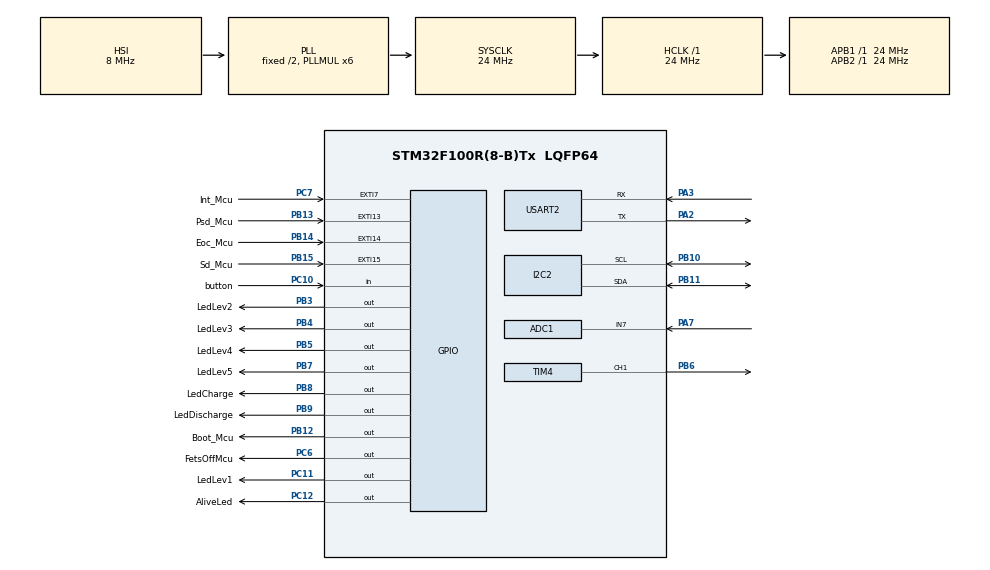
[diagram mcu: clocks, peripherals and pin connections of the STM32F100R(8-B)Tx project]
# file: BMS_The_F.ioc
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ADC1.Channel-0\#ChannelRegularConversion=ADC_CHANNEL_7
ADC1.ContinuousConvMode=DISABLE
ADC1.DataAlign=ADC_DATAALIGN_RIGHT
ADC1.DiscontinuousConvMode=DISABLE
ADC1.EnableAnalogWatchDog=false
ADC1.EnableRegularConversion=ENABLE
ADC1.ExternalTrigConv=ADC_SOFTWARE_START
ADC1.InjNumberOfConversion=0
ADC1.NbrOfConversion=1
ADC1.NbrOfConversionFlag=1
ADC1.Rank-0\#ChannelRegularConversion=1
ADC1.SamplingTime-0\#ChannelRegularConversion=ADC_SAMPLETIME_1CYCLE_5
ADC1.ScanConvMode=ADC_SCAN_DISABLE
ADC1.master=1
Mcu.Family=STM32F1
Mcu.Name=STM32F100R(8-B)Tx
Mcu.Package=LQFP64
NVIC.ADC1_IRQn=true\:0\:0\:false\:false\:true
NVIC.EXTI15_10_IRQn=true\:0\:0\:false\:false\:true
NVIC.EXTI9_5_IRQn=true\:0\:0\:false\:false\:true
NVIC.I2C2_ER_IRQn=true\:0\:0\:false\:false\:true
NVIC.I2C2_EV_IRQn=true\:0\:0\:false\:false\:true
NVIC.PriorityGroup=NVIC_PRIORITYGROUP_4
NVIC.TIM4_IRQn=true\:0\:0\:false\:false\:true
NVIC.USART2_IRQn=true\:0\:0\:false\:false\:true
PA13.Mode=Serial_Wire
PA13.Signal=SYS_JTMS-SWDIO
PA14.Mode=Serial_Wire
PA14.Signal=SYS_JTCK-SWCLK
PA2.Mode=Asynchronous
PA2.Signal=USART2_TX
PA3.Mode=Asynchronous
PA3.Signal=USART2_RX
PA7.Signal=ADCx_IN7
PB10.Mode=I2C
PB10.Signal=I2C2_SCL
PB11.Mode=I2C
PB11.Signal=I2C2_SDA
PB12.GPIO_Label=Boot_Mcu
PB12.Signal=GPIO_Output
PB13.GPIO_Label=Psd_Mcu
PB13.Signal=GPXTI13
PB14.GPIO_Label=Eoc_Mcu
PB14.Signal=GPXTI14
PB15.GPIO_Label=Sd_Mcu
PB15.Signal=GPXTI15
PB3.GPIO_Label=LedLev2
PB3.Signal=GPIO_Output
PB4.GPIO_Label=LedLev3
PB4.Signal=GPIO_Output
PB5.GPIO_Label=LedLev4
PB5.Signal=GPIO_Output
PB6.Signal=S_TIM4_CH1
PB7.GPIO_Label=LedLev5
PB7.Signal=GPIO_Output
PB8.GPIO_Label=LedCharge
PB8.Signal=GPIO_Output
PB9.GPIO_Label=LedDischarge
PB9.Signal=GPIO_Output
PC10.GPIO_Label=button
PC10.GPIO_PuPd=GPIO_PULLDOWN
PC10.Signal=GPIO_Input
PC11.GPIO_Label=LedLev1
PC11.Signal=GPIO_Output
PC12.GPIO_Label=AliveLed
PC12.Signal=GPIO_Output
PC6.GPIO_Label=FetsOffMcu
PC6.Signal=GPIO_Output
PC7.GPIO_Label=Int_Mcu
PC7.Signal=GPXTI7
ProjectManager.HeapSize=0x200
ProjectManager.StackSize=0x400
ProjectManager.TargetToolchain=MDK-ARM V5
RCC.AHBFreq_Value=24000000
RCC.APB1Freq_Value=24000000
RCC.APB1TimFreq_Value=24000000
RCC.APB2Freq_Value=24000000
RCC.APB2TimFreq_Value=24000000
RCC.HCLKFreq_Value=24000000
RCC.PLLMUL=RCC_PLL_MUL6
RCC.SYSCLKFreq_VALUE=24000000
RCC.SYSCLKSource=RCC_SYSCLKSOURCE_PLLCLK
SH.ADCx_IN7.0=ADC1_IN7,IN7
SH.S_TIM4_CH1.0=TIM4_CH1,PWM Generation1 CH1
TIM4.Channel-PWM\ Generation1\ CH1=TIM_CHANNEL_1
TIM4.Period=100
TIM4.Prescaler=12
TIM4.Pulse-PWM\ Generation1\ CH1=50
USART2.VirtualMode=VM_ASYNC
VP_TIM4_VS_ClockSourceINT.Mode=Internal
board=BMS_The_F

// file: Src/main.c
/**
  ******************************************************************************
  * File Name          : main.c
  * Description        : Main program body
  ******************************************************************************
  ** This notice applies to any and all portions of this file
  * that are not between comment pairs USER CODE BEGIN and
  * USER CODE END. Other portions of this file, whether
  * inserted by the user or by software development tools
  * are owned by their respective copyright owners.
  *
  * COPYRIGHT(c) 2017 STMicroelectronics
  *
  * Redistribution and use in source and binary forms, with or without modification,
  * are permitted provided that the following conditions are met:
  *   1. Redistributions of source code must retain the above copyright notice,
  *      this list of conditions and the following disclaimer.
  *   2. Redistributions in binary form must reproduce the above copyright notice,
  *      this list of conditions and the following disclaimer in the documentation
  *      and/or other materials provided with the distribution.
  *   3. Neither the name of STMicroelectronics nor the names of its contributors
  *      may be used to endorse or promote products derived from this software
  *      without specific prior written permission.
  *
  * THIS SOFTWARE IS PROVIDED BY THE COPYRIGHT HOLDERS AND CONTRIBUTORS "AS IS"
  * AND ANY EXPRESS OR IMPLIED WARRANTIES, INCLUDING, BUT NOT LIMITED TO, THE
  * IMPLIED WARRANTIES OF MERCHANTABILITY AND FITNESS FOR A PARTICULAR PURPOSE ARE
  * DISCLAIMED. IN NO EVENT SHALL THE COPYRIGHT HOLDER OR CONTRIBUTORS BE LIABLE
  * FOR ANY DIRECT, INDIRECT, INCIDENTAL, SPECIAL, EXEMPLARY, OR CONSEQUENTIAL
  * DAMAGES (INCLUDING, BUT NOT LIMITED TO, PROCUREMENT OF SUBSTITUTE GOODS OR
  * SERVICES; LOSS OF USE, DATA, OR PROFITS; OR BUSINESS INTERRUPTION) HOWEVER
  * CAUSED AND ON ANY THEORY OF LIABILITY, WHETHER IN CONTRACT, STRICT LIABILITY,
  * OR TORT (INCLUDING NEGLIGENCE OR OTHERWISE) ARISING IN ANY WAY OUT OF THE USE
  * OF THIS SOFTWARE, EVEN IF ADVISED OF THE POSSIBILITY OF SUCH DAMAGE.
  *
  ******************************************************************************
  */
#include "main.h"
#include "stm32f1xx_hal.h"
#include "ISL94202.h"                  // Device header
#include "ISL94202_I2C.h"                  // Device header

ADC_HandleTypeDef hadc1;

I2C_HandleTypeDef hi2c2;

TIM_HandleTypeDef htim4;

UART_HandleTypeDef huart2;

/* USER CODE BEGIN PV */
/* Private variables ---------------------------------------------------------*/
  volatile uint16_t voltages[9];
uint16_t i;
uint16_t z;
uint16_t q;
uint16_t w;
uint16_t e;
uint16_t r;
uint16_t t;
uint16_t y;

/* USER CODE END PV */

void SystemClock_Config(void);
static void MX_GPIO_Init(void);
static void MX_I2C2_Init(void);
static void MX_ADC1_Init(void);
static void MX_USART2_UART_Init(void);
static void MX_TIM4_Init(void);

void HAL_TIM_MspPostInit(TIM_HandleTypeDef *htim);

/* USER CODE BEGIN PFP */
/* Private function prototypes -----------------------------------------------*/

/* USER CODE END PFP */

int main(void)
{

  /* MCU Configuration----------------------------------------------------------*/

  /* Reset of all peripherals, Initializes the Flash interface and the Systick. */
  HAL_Init();

  /* Configure the system clock */
  SystemClock_Config();

  /* Initialize all configured peripherals */
  MX_GPIO_Init();
  MX_I2C2_Init();
  MX_ADC1_Init();
  MX_USART2_UART_Init();
  MX_TIM4_Init();

  /* USER CODE BEGIN 2 */
I2C_writeReg8( slaveAdd,  0x87,  0x40);

  /* USER CODE END 2 */

static uint8_t buffer[2];
  buffer[0]=0x85;
  buffer[1]=0x20;
	GPIO_PinState val;
  /* Infinite loop */
  while (1)
  {
		 val = HAL_GPIO_ReadPin(GPIOC, GPIO_PIN_10);
		if (val==1){
			I2C_writeReg8( slaveAdd,  0x86,  0x73);
		}else{
						I2C_writeReg8( slaveAdd,  0x86,  0x70);
 z = I2C_readReg8(slaveAdd, 0x86);

		}
	//	enableEEPROMAccess();
			//	             HAL_Delay(5);

							//	I2C_writeReg8( slaveAdd,  0x86,  0x70);
		         //    HAL_Delay(5);
            //
//HAL_I2C_Master_Transmit(&hi2c2,slaveAdd,buffer,2,100);

//ISL94202_updateReadings();
//I2C_writeReg8( slaveAdd,  0x85,  0x10);
//

//		//load in new I2C data
//
     //   volatile uint16_t voltages[9];
				//volatile uint16_t ampere[9];

           //voltages[i] = ISL94202_getCellVoltageMV(i);
 //i= ISL94202_getCellVoltageMV(i);

	/* for (i = 0; i < 8; i++){
 z= ISL94202_getCellVoltageMV(0);
 q= ISL94202_getCellVoltageMV(1);
 w= ISL94202_getCellVoltageMV(2);
 e= ISL94202_getCellVoltageMV(3);
 r= ISL94202_getCellVoltageMV(4);
 t= ISL94202_getCellVoltageMV(5);
 y= ISL94202_getCellVoltageMV(6);
 i= ISL94202_getCellVoltageMV(7);
*/
	//	for (z = 0; z < 4; z++)
	 					//ampere[1]=ISL94202_getPackCurrentMA(1);

//						ISL94202_updateStatus();

  }

}

/** System Clock Configuration
*/
void SystemClock_Config(void)
{

  RCC_OscInitTypeDef RCC_OscInitStruct;
  RCC_ClkInitTypeDef RCC_ClkInitStruct;
  RCC_PeriphCLKInitTypeDef PeriphClkInit;

    /**Initializes the CPU, AHB and APB busses clocks
    */
  RCC_OscInitStruct.OscillatorType = RCC_OSCILLATORTYPE_HSI;
  RCC_OscInitStruct.HSIState = RCC_HSI_ON;
  RCC_OscInitStruct.HSICalibrationValue = 16;
  RCC_OscInitStruct.PLL.PLLState = RCC_PLL_ON;
  RCC_OscInitStruct.PLL.PLLSource = RCC_PLLSOURCE_HSI_DIV2;
  RCC_OscInitStruct.PLL.PLLMUL = RCC_PLL_MUL6;
  if (HAL_RCC_OscConfig(&RCC_OscInitStruct) != HAL_OK)
  {
    _Error_Handler(__FILE__, __LINE__);
  }

    /**Initializes the CPU, AHB and APB busses clocks
    */
  RCC_ClkInitStruct.ClockType = RCC_CLOCKTYPE_HCLK|RCC_CLOCKTYPE_SYSCLK
                              |RCC_CLOCKTYPE_PCLK1|RCC_CLOCKTYPE_PCLK2;
  RCC_ClkInitStruct.SYSCLKSource = RCC_SYSCLKSOURCE_PLLCLK;
  RCC_ClkInitStruct.AHBCLKDivider = RCC_SYSCLK_DIV1;
  RCC_ClkInitStruct.APB1CLKDivider = RCC_HCLK_DIV1;
  RCC_ClkInitStruct.APB2CLKDivider = RCC_HCLK_DIV1;

  if (HAL_RCC_ClockConfig(&RCC_ClkInitStruct, FLASH_LATENCY_0) != HAL_OK)
  {
    _Error_Handler(__FILE__, __LINE__);
  }

  PeriphClkInit.PeriphClockSelection = RCC_PERIPHCLK_ADC;
  PeriphClkInit.AdcClockSelection = RCC_ADCPCLK2_DIV2;
  if (HAL_RCCEx_PeriphCLKConfig(&PeriphClkInit) != HAL_OK)
  {
    _Error_Handler(__FILE__, __LINE__);
  }

    /**Configure the Systick interrupt time
    */
  HAL_SYSTICK_Config(HAL_RCC_GetHCLKFreq()/1000);

    /**Configure the Systick
    */
  HAL_SYSTICK_CLKSourceConfig(SYSTICK_CLKSOURCE_HCLK);

  /* SysTick_IRQn interrupt configuration */
  HAL_NVIC_SetPriority(SysTick_IRQn, 0, 0);
}

/* ADC1 init function */
static void MX_ADC1_Init(void)
{

  ADC_ChannelConfTypeDef sConfig;

    /**Common config
    */
  hadc1.Instance = ADC1;
  hadc1.Init.ScanConvMode = ADC_SCAN_DISABLE;
  hadc1.Init.ContinuousConvMode = DISABLE;
  hadc1.Init.DiscontinuousConvMode = DISABLE;
  hadc1.Init.ExternalTrigConv = ADC_SOFTWARE_START;
  hadc1.Init.DataAlign = ADC_DATAALIGN_RIGHT;
  hadc1.Init.NbrOfConversion = 1;
  if (HAL_ADC_Init(&hadc1) != HAL_OK)
  {
    _Error_Handler(__FILE__, __LINE__);
  }

    /**Configure Regular Channel
    */
  sConfig.Channel = ADC_CHANNEL_7;
  sConfig.Rank = 1;
  sConfig.SamplingTime = ADC_SAMPLETIME_1CYCLE_5;
  if (HAL_ADC_ConfigChannel(&hadc1, &sConfig) != HAL_OK)
  {
    _Error_Handler(__FILE__, __LINE__);
  }

}

/* I2C2 init function */
static void MX_I2C2_Init(void)
{

  hi2c2.Instance = I2C2;
  hi2c2.Init.ClockSpeed = 100000;
  hi2c2.Init.DutyCycle = I2C_DUTYCYCLE_2;
  hi2c2.Init.OwnAddress1 = 0;
  hi2c2.Init.AddressingMode = I2C_ADDRESSINGMODE_7BIT;
  hi2c2.Init.DualAddressMode = I2C_DUALADDRESS_DISABLE;
  hi2c2.Init.OwnAddress2 = 0;
  hi2c2.Init.GeneralCallMode = I2C_GENERALCALL_DISABLE;
  hi2c2.Init.NoStretchMode = I2C_NOSTRETCH_DISABLE;
  if (HAL_I2C_Init(&hi2c2) != HAL_OK)
  {
    _Error_Handler(__FILE__, __LINE__);
  }

}

/* TIM4 init function */
static void MX_TIM4_Init(void)
{

  TIM_ClockConfigTypeDef sClockSourceConfig;
  TIM_MasterConfigTypeDef sMasterConfig;
  TIM_OC_InitTypeDef sConfigOC;

  htim4.Instance = TIM4;
  htim4.Init.Prescaler = 12;
  htim4.Init.CounterMode = TIM_COUNTERMODE_UP;
  htim4.Init.Period = 100;
  htim4.Init.ClockDivision = TIM_CLOCKDIVISION_DIV1;
  htim4.Init.AutoReloadPreload = TIM_AUTORELOAD_PRELOAD_DISABLE;
  if (HAL_TIM_Base_Init(&htim4) != HAL_OK)
  {
    _Error_Handler(__FILE__, __LINE__);
  }

  sClockSourceConfig.ClockSource = TIM_CLOCKSOURCE_INTERNAL;
  if (HAL_TIM_ConfigClockSource(&htim4, &sClockSourceConfig) != HAL_OK)
  {
    _Error_Handler(__FILE__, __LINE__);
  }

  if (HAL_TIM_PWM_Init(&htim4) != HAL_OK)
  {
    _Error_Handler(__FILE__, __LINE__);
  }

  sMasterConfig.MasterOutputTrigger = TIM_TRGO_RESET;
  sMasterConfig.MasterSlaveMode = TIM_MASTERSLAVEMODE_DISABLE;
  if (HAL_TIMEx_MasterConfigSynchronization(&htim4, &sMasterConfig) != HAL_OK)
  {
    _Error_Handler(__FILE__, __LINE__);
  }

  sConfigOC.OCMode = TIM_OCMODE_PWM1;
  sConfigOC.Pulse = 50;
  sConfigOC.OCPolarity = TIM_OCPOLARITY_HIGH;
  sConfigOC.OCFastMode = TIM_OCFAST_DISABLE;
  if (HAL_TIM_PWM_ConfigChannel(&htim4, &sConfigOC, TIM_CHANNEL_1) != HAL_OK)
  {
    _Error_Handler(__FILE__, __LINE__);
  }

  HAL_TIM_MspPostInit(&htim4);

}

/* USART2 init function */
static void MX_USART2_UART_Init(void)
{

  huart2.Instance = USART2;
  huart2.Init.BaudRate = 115200;
  huart2.Init.WordLength = UART_WORDLENGTH_8B;
  huart2.Init.StopBits = UART_STOPBITS_1;
  huart2.Init.Parity = UART_PARITY_NONE;
  huart2.Init.Mode = UART_MODE_TX_RX;
  huart2.Init.HwFlowCtl = UART_HWCONTROL_NONE;
  huart2.Init.OverSampling = UART_OVERSAMPLING_16;
  if (HAL_UART_Init(&huart2) != HAL_OK)
  {
    _Error_Handler(__FILE__, __LINE__);
  }

}

/** Configure pins as
        * Analog
        * Input
        * Output
        * EVENT_OUT
        * EXTI
*/
static void MX_GPIO_Init(void)
{

  GPIO_InitTypeDef GPIO_InitStruct;

  /* GPIO Ports Clock Enable */
  __HAL_RCC_GPIOA_CLK_ENABLE();
  __HAL_RCC_GPIOB_CLK_ENABLE();
  __HAL_RCC_GPIOC_CLK_ENABLE();

  /*Configure GPIO pin Output Level */
  HAL_GPIO_WritePin(GPIOB, Boot_Mcu_Pin|LedLev2_Pin|LedLev3_Pin|LedLev4_Pin
                          |LedLev5_Pin|LedCharge_Pin|LedDischarge_Pin, GPIO_PIN_RESET);

  /*Configure GPIO pin Output Level */
  HAL_GPIO_WritePin(GPIOC, FetsOffMcu_Pin|LedLev1_Pin|AliveLed_Pin, GPIO_PIN_RESET);

  /*Configure GPIO pins : Boot_Mcu_Pin LedLev2_Pin LedLev3_Pin LedLev4_Pin
                           LedLev5_Pin LedCharge_Pin LedDischarge_Pin */
  GPIO_InitStruct.Pin = Boot_Mcu_Pin|LedLev2_Pin|LedLev3_Pin|LedLev4_Pin
                          |LedLev5_Pin|LedCharge_Pin|LedDischarge_Pin;
  GPIO_InitStruct.Mode = GPIO_MODE_OUTPUT_PP;
  GPIO_InitStruct.Speed = GPIO_SPEED_FREQ_LOW;
  HAL_GPIO_Init(GPIOB, &GPIO_InitStruct);

  /*Configure GPIO pins : Psd_Mcu_Pin Eoc_Mcu_Pin Sd_Mcu_Pin */
  GPIO_InitStruct.Pin = Psd_Mcu_Pin|Eoc_Mcu_Pin|Sd_Mcu_Pin;
  GPIO_InitStruct.Mode = GPIO_MODE_IT_RISING;
  GPIO_InitStruct.Pull = GPIO_NOPULL;
  HAL_GPIO_Init(GPIOB, &GPIO_InitStruct);

  /*Configure GPIO pins : FetsOffMcu_Pin LedLev1_Pin AliveLed_Pin */
  GPIO_InitStruct.Pin = FetsOffMcu_Pin|LedLev1_Pin|AliveLed_Pin;
  GPIO_InitStruct.Mode = GPIO_MODE_OUTPUT_PP;
  GPIO_InitStruct.Speed = GPIO_SPEED_FREQ_LOW;
  HAL_GPIO_Init(GPIOC, &GPIO_InitStruct);

  /*Configure GPIO pin : Int_Mcu_Pin */
  GPIO_InitStruct.Pin = Int_Mcu_Pin;
  GPIO_InitStruct.Mode = GPIO_MODE_IT_RISING;
  GPIO_InitStruct.Pull = GPIO_NOPULL;
  HAL_GPIO_Init(Int_Mcu_GPIO_Port, &GPIO_InitStruct);

  /*Configure GPIO pin : button_Pin */
  GPIO_InitStruct.Pin = button_Pin;
  GPIO_InitStruct.Mode = GPIO_MODE_INPUT;
  GPIO_InitStruct.Pull = GPIO_PULLDOWN;
  HAL_GPIO_Init(button_GPIO_Port, &GPIO_InitStruct);

  /* EXTI interrupt init*/
  HAL_NVIC_SetPriority(EXTI9_5_IRQn, 0, 0);
  HAL_NVIC_EnableIRQ(EXTI9_5_IRQn);

  HAL_NVIC_SetPriority(EXTI15_10_IRQn, 0, 0);
  HAL_NVIC_EnableIRQ(EXTI15_10_IRQn);

}

void _Error_Handler(char * file, int line)
{
  while(1)
  {
  }
}

/************************ (C) COPYRIGHT STMicroelectronics *****END OF FILE****/
